# A31G324 register map
Vendor: ABOV Semiconductor Co., Ltd.; Series: A31G324; File version: 1.0
CPU: CM0PLUS r0p1, little endian, no MPU, no FPU, VTOR, 2 interrupt priority bits
Registers are 32-bit, read-write, reset 0x0 unless marked. A register's access mark holds for its fields unless they carry their own. Offsets are from the block's base; [hi:lo] are bit positions; {n}, {i} and the like mark numbered series.

## RTC — Real-time clock
Base 0x40006100
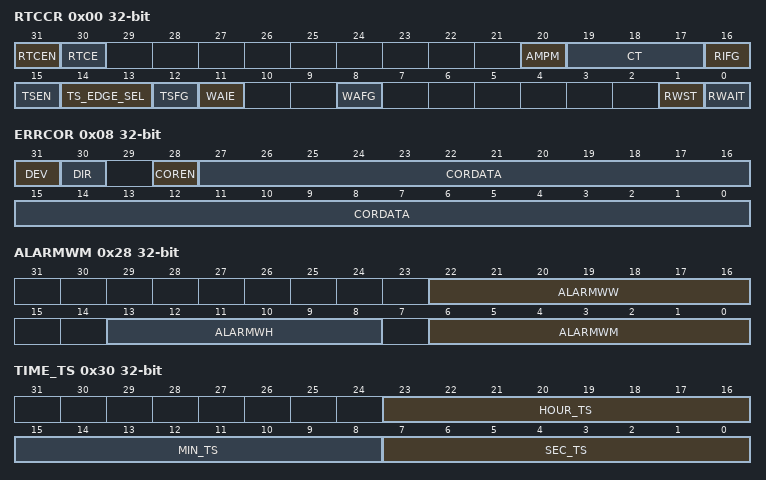
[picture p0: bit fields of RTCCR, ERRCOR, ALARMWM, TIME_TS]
0x00 RTCCR — RTC Control Register
  [31] RTCEN — RTC clock input enable
  [30] RTCE — RTC counter run
  [20] AMPM — Hour system selection
  [19:17] CT — Period selection of constant-period matching
  [16] RIFG — Constant-period matching flag
  [15] TSEN — Timestamp enable
  [14:13] TS_EDGE_SEL — Timestamp event active edge selection
  [12] TSFG — Time stamp event flag
  [11] WAIE — Alarm enable
  [8] WAFG — Alarm flag
  [1] RWST — RW mode status flag
  [0] RWAIT — RW mode set
0x08 ERRCOR (reset mask 0xDFFFFFF) — Error Correction Register
  [31] DEV — Setting of watch error correction timing.
  [30] DIR — Setting of watch error correction direction
  [28] COREN — Enable watch error correction
  [27:0] CORDATA — Setting of watch error correction data When CORDATA=0, the watch error is not corrected.
0x0C SEC — Second Count Register
  [6:0] SEC — The SEC register is an 8-bit register that takes a value of 0 to 59 (decimal) and indicates the count value of seconds. It counts up when the sub-count register overflows. When data is written to this register, it is written to a buffer and then to the counter when RWST bit is changed to '0'. Set a decimal value of 00 to 59 to this register in BCD code. If a value that is not a BCD code is written, it is ignored. If a value outside the range is written, the reset value is set.
0x10 MIN — Minute Count Register
  [6:0] MIN — The MIN register is an 8-bit register that takes a value of 0 to 59 (decimal) and indicates the count value of minutes. It counts up when the second counter overflows. When data is written to this register, it is written to a buffer and then to the counter when RWST bit is changed to '0'. Even if the second count register overflows while this register is being written, this register ignores the overflow and is set to the value written. Set a decimal value of 00 to 59 to this register in BCD code. If a value that is not a BCD code is written, it is ignored. If a value outside the range is written, the reset value is set.
0x14 HOUR — Hour Count Register
  [5:0] HOUR — The HOUR register is an 8-bit register that takes a value of 00 to 23 or 01 to 12 and 21 to 32 (decimal) and indicates the count value of hours. It counts up when the minute counter overflows.
0x18 DAY — Day Count Register
  [5:0] DAY — The DAY register is an 8-bit register that takes a value of 1 to 31 (decimal) and indicates the count value of days. It counts up when the hour counter overflows.
0x1C WEEK — Week Count Register
  [2:0] WEEK — The WEEK register is an 8-bit register that takes a value of 0 to 6 (decimal) and indicates the count value of weekdays. It counts up in synchronization with the day counter.
0x20 MONTH — Month Count Register
  [4:0] MONTH — The MONTH register is an 8-bit register that takes a value of 1 to 12 (decimal) and indicates the count value of months. It counts up when the day counter overflows.
0x24 YEAR — Year Count Register
  [7:0] YEAR — The YEAR register is an 8-bit register that takes a value of 0 to 99 (decimal) and indicates the count value of years.
0x28 ALARMWM — Alarm Register
  [22:16] ALARMWW — This register is used to set day of the week for the alarm. Each of the seven bits represents a day of the week, so that duplicate days of the week can be selected.
  [13:8] ALARMWH — This register is used to set hours of the alarm. Set a decimal value of 00 to 23, 01 to 12, or 21 to 32 to this register according to AMPM in BCD code. If a value outside the range is set, the alarm is not detected.
  [6:0] ALARMWM — This register is used to set minutes of the alarm. Set a decimal value of 00 to 59 to this register in BCD code. If a value outside the range is set, the alarm is not detected.
0x2C SUBDR — Sub-second counter Compare Reigster
0x30 TIME_TS — TimeStamp Time Reigster
  [23:16] HOUR_TS — HOUR stored when the timestamp event occurred
  [15:8] MIN_TS — MIN stored when the timestamp event occurred
  [7:0] SEC_TS — SEC stored when the timestamp event occurred
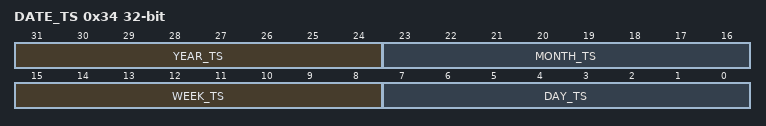
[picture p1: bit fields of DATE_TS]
0x34 DATE_TS — TimeStamp Date Reigster
  [31:24] YEAR_TS — YEAR stored when the timestamp event occurred
  [23:16] MONTH_TS — MONTH stored when the timestamp event occurred
  [15:8] WEEK_TS — WEEK stored when the timestamp event occurred
  [7:0] DAY_TS — DAY stored when the timestamp event occurred
{0x34+4i} BKUPDR{i} (i=1..4) — Backup Register {i}
  [31:0] BKUPDR — Backup Register
0x48 RTCPFCR — RTC Pin Function Configuration Register
  [10] PC13WK_EDGE — PC13 wakeup event occurrence mode (level or edge)
  [10:9] PC13WKPOL — PC13 wakeup event occurrence mode (polarity)
  [7] PC15MODE
  [6] PC15VALUE — PC15 value If the LSE is disabled and PC15MODE=1, PC15VALUE configures the PC15 output data
  [5] PC14MODE
  [4] PC14VALUE — PC14 value If the LSE is disabled and PC14MODE=1, PC14VALUE configures the PC14 output data
  [3:2] PC13MODE
  [1] PC13VALUE — PC13 value If PC13MODE=01, PC13VALUE configures the PC13 output data
  [0] PC13WKUEN — Wakeup pin enable
